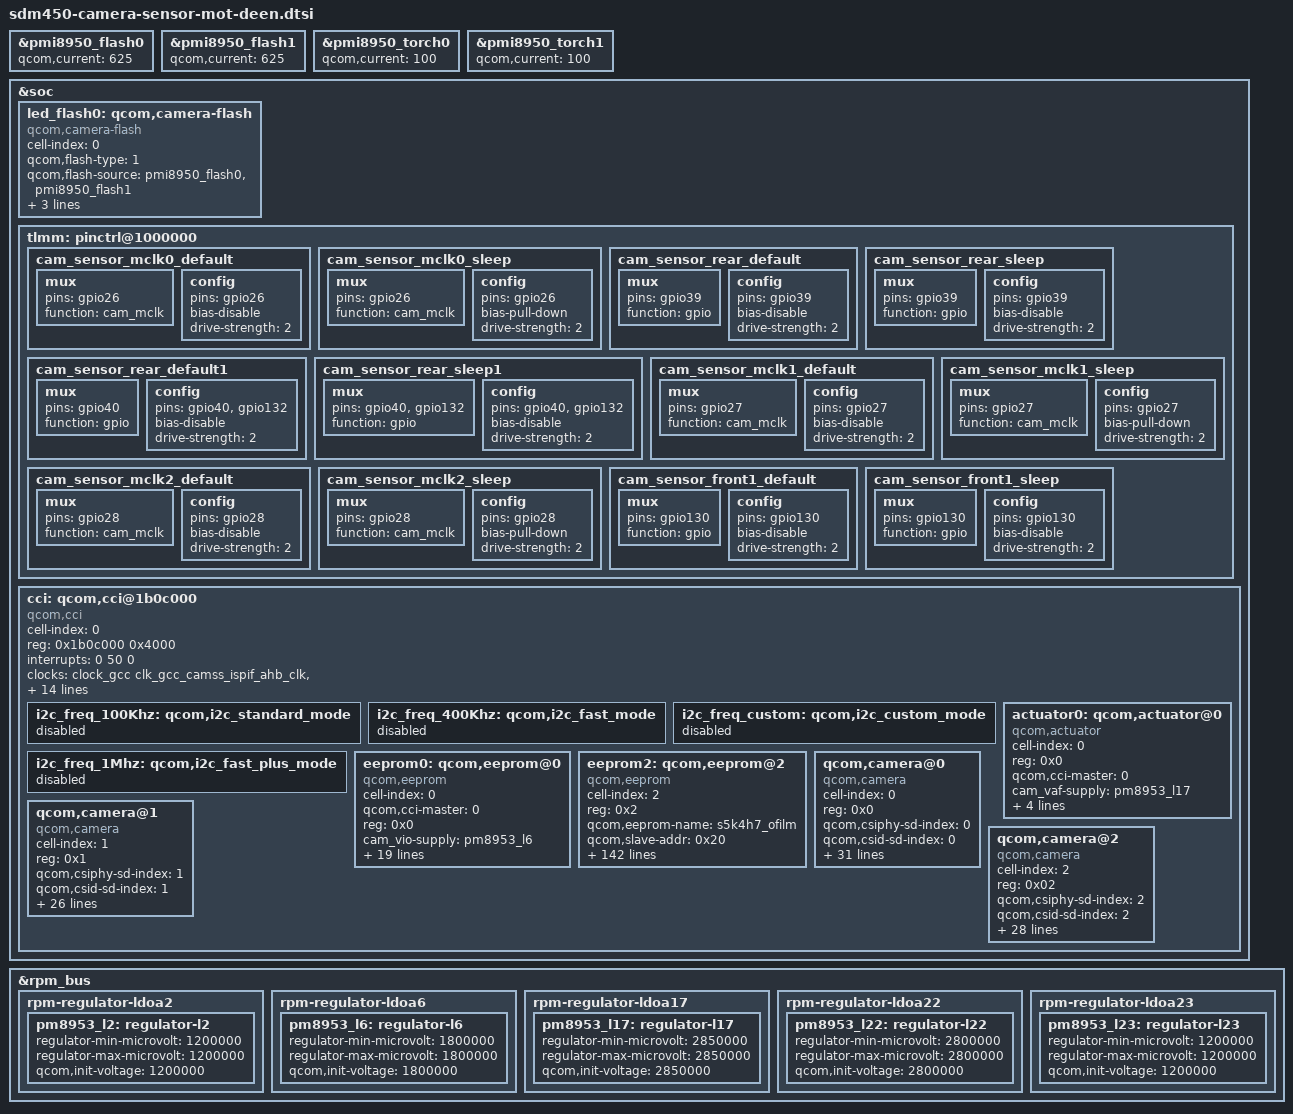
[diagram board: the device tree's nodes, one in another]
/*
 * Copyright (c) 2018, The Linux Foundation. All rights reserved.
 *
 * This program is free software; you can redistribute it and/or modify
 * it under the terms of the GNU General Public License version 2 and
 * only version 2 as published by the Free Software Foundation.
 *
 * This program is distributed in the hope that it will be useful,
 * but WITHOUT ANY WARRANTY; without even the implied warranty of
 * MERCHANTABILITY or FITNESS FOR A PARTICULAR PURPOSE.  See the
 * GNU General Public License for more details.
 */
&pmi8950_flash0 {
	qcom,current = <625>;
};

&pmi8950_flash1 {
	qcom,current = <625>;
};

&pmi8950_torch0 {
	qcom,current = <100>;
};

&pmi8950_torch1 {
	qcom,current = <100>;
};

&soc {
	led_flash0: qcom,camera-flash {
		cell-index = <0>;
		compatible = "qcom,camera-flash";
		qcom,flash-type = <1>;
		qcom,flash-source = <&pmi8950_flash0 &pmi8950_flash1>;
		qcom,torch-source = <&pmi8950_torch0 &pmi8950_torch1>;
		qcom,switch-source = <&pmi8950_switch>;
	};
};

&cci {
	actuator0: qcom,actuator@0 {
		cell-index = <0>;
		reg = <0x0>;
		compatible = "qcom,actuator";
		qcom,cci-master = <0>;
		cam_vaf-supply = <&pm8953_l17>;
		qcom,cam-vreg-name = "cam_vaf";
		qcom,cam-vreg-min-voltage = <2850000>;
		qcom,cam-vreg-max-voltage = <2850000>;
		qcom,cam-vreg-op-mode = <80000>;
	};

	eeprom0: qcom,eeprom@0 {
		cell-index = <0>;
		compatible = "qcom,eeprom";
		qcom,cci-master = <0>;
		reg = <0x0>;
		cam_vio-supply = <&pm8953_l6>;
		cam_vdig-supply = <&pm8953_l2>;
		cam_vaf-supply = <&pm8953_l17>;
		qcom,cam-vreg-name = "cam_vio", "cam_vdig", "cam_vaf";
		qcom,cam-vreg-min-voltage = <0 1200000 2850000>;
		qcom,cam-vreg-max-voltage = <0 1200000 2850000>;
		qcom,cam-vreg-op-mode = <0 105000 100000>;
		pinctrl-names = "cam_default", "cam_suspend";
		pinctrl-0 = <&cam_sensor_mclk0_default
				&cam_sensor_rear_default>;
		pinctrl-1 = <&cam_sensor_mclk0_sleep
				&cam_sensor_rear_sleep>;
		gpios = <&tlmm 26 0>,
			<&tlmm 39 0>;
		qcom,gpio-reset = <1>;
		qcom,gpio-req-tbl-num = <0 1>;
		qcom,gpio-req-tbl-flags = <1 0>;
		qcom,gpio-req-tbl-label = "CAMIF_MCLK0",
			"CAM_RESET0";
		status = "ok";
		clocks = <&clock_gcc clk_mclk0_clk_src>,
				<&clock_gcc clk_gcc_camss_mclk0_clk>;
		clock-names = "cam_src_clk", "cam_clk";
		qcom,clock-rates = <24000000 0>;
	};



	eeprom2: qcom,eeprom@2 {
		cell-index = <2>;
		reg = <0x2>;
		compatible = "qcom,eeprom";
		qcom,eeprom-name = "s5k4h7_ofilm";
		qcom,slave-addr = <0x20>;
		qcom,cci-master = <1>;
		qcom,num-blocks = <36>;

		qcom,cmm-data-support = <1>;
		qcom,cmm-data-compressed = <0>;
		qcom,cmm-data-offset = <10>;
		qcom,cmm-data-size = <20>;

		//read page 21
		qcom,page0 = <1 0x0100 2 0x01 1 0>;//STREAM ON
		qcom,poll0 = <0 0x0 2 0x0 1 0>;
		qcom,mem0 = <0 0x0 2 0x0 1 0>;

		qcom,page1 = <1 0x0A02 2 0x15 1 0>;//PAGE 20
		qcom,poll1 = <0 0x0 2 0x0 1 0>;
		qcom,mem1 = <0 0x0 2 0x0 1 0>;

		qcom,page2 = <1 0x0A00 2 0x01 1 0>;//ENABLE READ
		qcom,poll2 = <0 0x0 2 0x0 1 0>;
		qcom,mem2 = <64 0x0A04 2 0x0 1 0>;//READ PAGE 20
		//read page 22
		qcom,page3 = <1 0x0100 2 0x01 1 0>;
		qcom,poll3 = <0 0x0 2 0x0 1 0>;
		qcom,mem3 = <0 0x0 2 0x0 1 0>;

		qcom,page4 = <1 0x0A02 2 0x16 1 0>;
		qcom,poll4 = <0 0x0 2 0x0 1 0>;
		qcom,mem4 = <0 0x0 2 0x0 1 0>;

		qcom,page5 = <1 0x0A00 2 0x01 1 0>;
		qcom,poll5 = <0 0x0 2 0x0 1 0>;
		qcom,mem5 = <64 0x0A04 2 0x0 1 0>;
		//read page 23

		qcom,page6 = <1 0x0100 2 0x01 1 0>;
		qcom,poll6 = <0 0x0 2 0x0 1 0>;
		qcom,mem6 = <0 0x0 2 0x0 1 0>;

		qcom,page7 = <1 0x0A02 2 0x17 1 0>;
		qcom,poll7 = <0 0x0 2 0x0 1 0>;
		qcom,mem7 = <0 0x0 2 0x0 1 0>;

		qcom,page8 = <1 0x0A00 2 0x01 1 0>;
		qcom,poll8 = <0 0x0 2 0x0 1 0>;
		qcom,mem8 = <64 0x0A04 2 0x0 1 0>;//tes1 pass


		//read page 24
		qcom,page9 = <1 0x0100 2 0x01 1 0>;
		qcom,poll9 = <0 0x0 2 0x0 1 0>;
		qcom,mem9 = <0 0x0 2 0x0 1 0>;

		qcom,page10 = <1 0x0A02 2 0x18 1 0>;
		qcom,poll10 = <0 0x0 2 0x0 1 0>;
		qcom,mem10 = <0 0x0 2 0x0 1 0>;

		qcom,page11 = <1 0x0A00 2 0x01 1 0>;
		qcom,poll11 = <0 0x0 2 0x0 1 0>;
		qcom,mem11 = <64 0x0A04 2 0x0 1 0>;
		//read page 25
		qcom,page12 = <1 0x0100 2 0x01 1 0>;
		qcom,poll12 = <0 0x0 2 0x0 1 0>;
		qcom,mem12 = <0 0x0 2 0x0 1 0>;

		qcom,page13 = <1 0x0A02 2 0x19 1 0>;
		qcom,poll13 = <0 0x0 2 0x0 1 0>;
		qcom,mem13 = <0 0x0 2 0x0 1 0>;

		qcom,page14 = <1 0x0A00 2 0x01 1 0>;
		qcom,poll14 = <0 0x0 2 0x0 1 0>;
		qcom,mem14 = <64 0x0A04 2 0x0 1 0>;

		//read page 26
		qcom,page15 = <1 0x0100 2 0x01 1 0>;
		qcom,poll15 = <0 0x0 2 0x0 1 0>;
		qcom,mem15 = <0 0x0 2 0x0 1 0>;

		qcom,page16 = <1 0x0A02 2 0x1A 1 0>;
		qcom,poll16 = <0 0x0 2 0x0 1 0>;
		qcom,mem16 = <0 0x0 2 0x0 1 0>;

		qcom,page17 = <1 0x0A00 2 0x01 1 0>;
		qcom,poll17 = <0 0x0 2 0x0 1 0>;
		qcom,mem17 = <64 0x0A04 2 0x0 1 0>;

		//read page 27
		qcom,page18 = <1 0x0100 2 0x01 1 0>;
		qcom,poll18 = <0 0x0 2 0x0 1 0>;
		qcom,mem18 = <0 0x0 2 0x0 1 0>;

		qcom,page19 = <1 0x0A02 2 0x1B 1 0>;
		qcom,poll19 = <0 0x0 2 0x0 1 0>;
		qcom,mem19 = <0 0x0 2 0x0 1 0>;

		qcom,page20 = <1 0x0A00 2 0x01 1 0>;
		qcom,poll20 = <0 0x0 2 0x0 1 0>;
		qcom,mem20 = <64 0x0A04 2 0x0 1 0>;
		//read page 28
		qcom,page21 = <1 0x0100 2 0x01 1 0>;
		qcom,poll21 = <0 0x0 2 0x0 1 0>;
		qcom,mem21 = <0 0x0 2 0x0 1 0>;

		qcom,page22 = <1 0x0A02 2 0x1C 1 0>;
		qcom,poll22 = <0 0x0 2 0x0 1 0>;
		qcom,mem22 = <0 0x0 2 0x0 1 0>;

		qcom,page23 = <1 0x0A00 2 0x01 1 0>;
		qcom,poll23 = <0 0x0 2 0x0 1 0>;
		qcom,mem23 = <64 0x0A04 2 0x0 1 0>;

		//read page 29
		qcom,page24 = <1 0x0100 2 0x01 1 0>;
		qcom,poll24 = <0 0x0 2 0x0 1 0>;
		qcom,mem24 = <0 0x0 2 0x0 1 0>;

		qcom,page25 = <1 0x0A02 2 0x1D 1 0>;
		qcom,poll25 = <0 0x0 2 0x0 1 0>;
		qcom,mem25 = <0 0x0 2 0x0 1 0>;

		qcom,page26 = <1 0x0A00 2 0x01 1 0>;
		qcom,poll26 = <0 0x0 2 0x0 1 0>;
		qcom,mem26 = <64 0x0A04 2 0x0 1 0>;

		//read page 30
		qcom,page27 = <1 0x0100 2 0x01 1 0>;
		qcom,poll27 = <0 0x0 2 0x0 1 0>;
		qcom,mem27 = <0 0x0 2 0x0 1 0>;

		qcom,page28 = <1 0x0A02 2 0x1E 1 0>;
		qcom,poll28 = <0 0x0 2 0x0 1 0>;
		qcom,mem28 = <0 0x0 2 0x0 1 0>;

		qcom,page29 = <1 0x0A00 2 0x01 1 0>;
		qcom,poll29 = <0 0x0 2 0x0 1 0>;
		qcom,mem29 = <64 0x0A04 2 0x0 1 0>;//test2 failed

		//read page 31
		qcom,page30 = <1 0x0100 2 0x01 1 0>;
		qcom,poll30 = <0 0x0 2 0x0 1 0>;
		qcom,mem30 = <0 0x0 2 0x0 1 0>;

		qcom,page31 = <1 0x0A02 2 0x1F 1 0>;
		qcom,poll31 = <0 0x0 2 0x0 1 0>;
		qcom,mem31 = <0 0x0 2 0x0 1 0>;

		qcom,page32 = <1 0x0A00 2 0x01 1 0>;
		qcom,poll32 = <0 0x0 2 0x0 1 0>;
		qcom,mem32 = <64 0x0A04 2 0x0 1 0>;

		//read page 32
		qcom,page33 = <1 0x0100 2 0x01 1 0>;
		qcom,poll33 = <0 0x0 2 0x0 1 0>;
		qcom,mem33 = <0 0x0 2 0x0 1 0>;

		qcom,page34 = <1 0x0A02 2 0x20 1 0>;
		qcom,poll34 = <0 0x0 2 0x0 1 0>;
		qcom,mem34 = <0 0x0 2 0x0 1 0>;

		qcom,page35 = <1 0x0A00 2 0x01 1 0>;
		qcom,poll35 = <0 0x0 2 0x0 1 0>;
		qcom,mem35 = <64 0x0A04 2 0x0 1 0>;

		cam_vdig-supply = <&pm8953_l23>;
		cam_vio-supply = <&pm8953_l6>;
		cam_vana-supply = <&pm8953_l22>;
		qcom,cam-vreg-name = "cam_vdig", "cam_vio", "cam_vana";
		qcom,cam-vreg-min-voltage = <1200000 0 2800000>;
		qcom,cam-vreg-max-voltage = <1200000 0 2800000>;
		qcom,cam-vreg-op-mode = <105000 0 80000>;
		pinctrl-names = "cam_default", "cam_suspend";
		pinctrl-0 = <&cam_sensor_mclk1_default
			&cam_sensor_front1_default>;
		pinctrl-1 = <&cam_sensor_mclk1_sleep
			&cam_sensor_front1_sleep>;
		gpios = <&tlmm 27 0>,
			<&tlmm 130 0>;
		qcom,gpio-reset = <1>;
		qcom,gpio-req-tbl-num = <0 1>;
		qcom,gpio-req-tbl-flags = <1 0>;
		qcom,gpio-req-tbl-label = "CAMIF_MCLK2", "CAM_RESET2";

		qcom,cam-power-seq-type = "sensor_vreg",
			"sensor_vreg", "sensor_vreg",
			"sensor_gpio", "sensor_clk";
		qcom,cam-power-seq-val = "cam_vana",
			"cam_vdig", "cam_vio",
			"sensor_gpio_reset",
			"sensor_cam_mclk";
		qcom,cam-power-seq-cfg-val = <0 0 0 1 24000000>;
		qcom,cam-power-seq-delay = <1 1 5 5 5>;

		status = "ok";
		clocks = <&clock_gcc clk_mclk1_clk_src>,
				<&clock_gcc clk_gcc_camss_mclk1_clk>;
		clock-names = "cam_src_clk", "cam_clk";
		qcom,clock-rates = <24000000 0>;
	};

	/* OV13855 REAR */
	qcom,camera@0 {
		cell-index = <0>;
		compatible = "qcom,camera";
		reg = <0x0>;
		qcom,csiphy-sd-index = <0>;
		qcom,csid-sd-index = <0>;
		qcom,mount-angle = <90>;
		qcom,led-flash-src = <&led_flash0>;
		qcom,actuator-src = <&actuator0>;
		qcom,eeprom-src = <&eeprom0>;
		cam_vio-supply = <&pm8953_l6>;
		cam_vdig-supply = <&pm8953_l2>;
		cam_vaf-supply = <&pm8953_l17>;
		cam_vana-supply = <&pm8953_l22>;

		qcom,cam-vreg-name = "cam_vio", "cam_vdig", "cam_vaf",
						"cam_vana";
		qcom,cam-vreg-min-voltage = <0 1200000 2850000 2800000>;
		qcom,cam-vreg-max-voltage = <0 1200000 2850000 2800000>;
		qcom,cam-vreg-op-mode = <0 105000 100000 80000>;
		pinctrl-names = "cam_default", "cam_suspend";
		pinctrl-0 = <&cam_sensor_mclk0_default
				&cam_sensor_rear_default>;
		pinctrl-1 = <&cam_sensor_mclk0_sleep &cam_sensor_rear_sleep>;
		gpios = <&tlmm 26 0>,
			<&tlmm 39 0>;
		qcom,gpio-reset = <1>;
		qcom,gpio-req-tbl-num = <0 1>;
		qcom,gpio-req-tbl-flags = <1 0>;
		qcom,gpio-req-tbl-label = "CAMIF_MCLK0",
			"CAM_RESET0";
		qcom,sensor-position = <0>;
		qcom,sensor-mode = <0>;
		qcom,cci-master = <0>;
		status = "ok";
		clocks = <&clock_gcc clk_mclk0_clk_src>,
				<&clock_gcc clk_gcc_camss_mclk0_clk>;
		clock-names = "cam_src_clk", "cam_clk";
		qcom,clock-rates = <24000000 0>;
	};
/*gc2375 backaux */
	qcom,camera@1 {
		cell-index = <1>;
		compatible = "qcom,camera";
		reg = <0x1>;
		qcom,csiphy-sd-index = <1>;
		qcom,csid-sd-index = <1>;
		qcom,mount-angle = <90>;
		//qcom,eeprom-src = <&eeprom2>;
		cam_vdig-supply = <&pm8953_l6>;
		cam_vana-supply = <&pm8953_l22>;
		cam_vio-supply = <&pm8953_l6>;
		qcom,cam-vreg-name = "cam_vdig", "cam_vio", "cam_vana";
		qcom,cam-vreg-min-voltage = <1800000 0 2800000>;
		qcom,cam-vreg-max-voltage = <1800000 0 2800000>;
		qcom,cam-vreg-op-mode = <200000 0 80000>;
		pinctrl-names = "cam_default", "cam_suspend";
		pinctrl-0 = <&cam_sensor_mclk2_default
				&cam_sensor_rear_default1>;
		pinctrl-1 = <&cam_sensor_mclk2_sleep
				&cam_sensor_rear_sleep1>;
		gpios = <&tlmm 28 0>,
			<&tlmm 40 0>,
			<&tlmm 132 0>;
		qcom,gpio-reset = <1>;
		qcom,gpio-standby = <2>;
		qcom,gpio-req-tbl-num = <0 1 2>;
		qcom,gpio-req-tbl-flags = <1 0 0>;
		qcom,gpio-req-tbl-label = "CAMIF_MCLK1",
			"CAM_RESET1",
			"CAM_STANDBY1";
		qcom,sensor-position = <0x000>;
		qcom,sensor-mode = <0>;
		qcom,cci-master = <0>;
		status = "ok";
		clocks = <&clock_gcc clk_mclk2_clk_src>,
				<&clock_gcc clk_gcc_camss_mclk2_clk>;
		clock-names = "cam_src_clk", "cam_clk";
		qcom,clock-rates = <24000000 0>;
	};

	/* S5K4H7 */
	qcom,camera@2 {
		cell-index = <2>;
		compatible = "qcom,camera";
		reg = <0x02>;
		qcom,csiphy-sd-index = <2>;
		qcom,csid-sd-index = <2>;
		qcom,mount-angle = <90>;
		qcom,led-flash-src = <&led_flash0>;
		qcom,eeprom-src = <&eeprom2>;
		cam_vdig-supply = <&pm8953_l23>;
		cam_vio-supply = <&pm8953_l6>;
		cam_vana-supply = <&pm8953_l22>;
		qcom,cam-vreg-name = "cam_vdig", "cam_vio", "cam_vana";
		qcom,cam-vreg-min-voltage = <1200000 0 2800000>;
		qcom,cam-vreg-max-voltage = <1200000 0 2800000>;
		qcom,cam-vreg-op-mode = <105000 0 80000>;
		qcom,gpio-no-mux = <0>;
		pinctrl-names = "cam_default", "cam_suspend";
		pinctrl-0 = <&cam_sensor_mclk1_default
				&cam_sensor_front1_default>;
		pinctrl-1 = <&cam_sensor_mclk1_sleep
				&cam_sensor_front1_sleep>;
		gpios = <&tlmm 27 0>,
			<&tlmm 130 0>;
		qcom,gpio-reset = <1>;
		qcom,gpio-req-tbl-num = <0 1>;
		qcom,gpio-req-tbl-flags = <1 0>;
		qcom,gpio-req-tbl-label = "CAMIF_MCLK2",
					  "CAM_RESET2";
		qcom,sensor-position = <1>;
		qcom,sensor-mode = <1>;
		qcom,cci-master = <1>;
		status = "ok";
		clocks = <&clock_gcc clk_mclk1_clk_src>,
				<&clock_gcc clk_gcc_camss_mclk1_clk>;
		clock-names = "cam_src_clk", "cam_clk";
		qcom,clock-rates = <24000000 0>;
	};

};

&soc {
	tlmm: pinctrl@1000000 {

		cam_sensor_mclk0_default: cam_sensor_mclk0_default {
			/* MCLK0 */
			mux {
				/* CLK, DATA */
				pins = "gpio26";
				function = "cam_mclk";
			};

			config {
				pins = "gpio26";
				bias-disable; /* No PULL */
				drive-strength = <2>; /* 2 MA */
			};
		};

		cam_sensor_mclk0_sleep: cam_sensor_mclk0_sleep {
			/* MCLK0 */
			mux {
				/* CLK, DATA */
				pins = "gpio26";
				function = "cam_mclk";
			};

			config {
				pins = "gpio26";
				bias-pull-down; /* PULL DOWN */
				drive-strength = <2>; /* 2 MA */
			};
		};

		cam_sensor_rear_default: cam_sensor_rear_default {
				/* RESET, STANDBY */
			mux {
					pins = "gpio39";
				function = "gpio";
			};

				config {
					pins = "gpio39";
					bias-disable; /* No PULL */
					drive-strength = <2>; /* 2 MA */
				};
			};

			cam_sensor_rear_sleep: cam_sensor_rear_sleep {
				/* RESET, STANDBY */
				mux {
					pins = "gpio39";
					function = "gpio";
				};

				config {
					pins = "gpio39";
					bias-disable; /* No PULL */
					drive-strength = <2>; /* 2 MA */
				};
			};

		cam_sensor_rear_default1: cam_sensor_rear_default1 {
			/* RESET*/
			mux {
				pins = "gpio40";
				function = "gpio";
			};

				config {
					pins = "gpio40","gpio132";
					bias-disable; /* No PULL */
					drive-strength = <2>; /* 2 MA */
				};
			};

			cam_sensor_rear_sleep1: cam_sensor_rear_sleep1 {
				/* RESET*/
				mux {
					pins = "gpio40","gpio132";
					function = "gpio";
				};

				config {
					pins = "gpio40","gpio132";
					bias-disable; /* No PULL */
					drive-strength = <2>; /* 2 MA */
				};
			};

		cam_sensor_mclk1_default: cam_sensor_mclk1_default {
			/* MCLK1 */
			mux {
				/* CLK, DATA */
				pins = "gpio27";
				function = "cam_mclk";
			};

			config {
				pins = "gpio27";
				bias-disable; /* No PULL */
				drive-strength = <2>; /* 2 MA */
			};
		};

		cam_sensor_mclk1_sleep: cam_sensor_mclk1_sleep {
			/* MCLK1 */
			mux {
				/* CLK, DATA */
				pins = "gpio27";
				function = "cam_mclk";
			};

			config {
				pins = "gpio27";
				bias-pull-down; /* PULL DOWN */
				drive-strength = <2>; /* 2 MA */
			};
		};


		cam_sensor_mclk2_default: cam_sensor_mclk2_default {
			/* MCLK2 */
			mux {
				/* CLK, DATA */
				pins = "gpio28";
				function = "cam_mclk";
			};

			config {
				pins = "gpio28";
				bias-disable; /* No PULL */
				drive-strength = <2>; /* 2 MA */
			};
		};

		cam_sensor_mclk2_sleep: cam_sensor_mclk2_sleep {
			/* MCLK2 */
			mux {
				/* CLK, DATA */
				pins = "gpio28";
				function = "cam_mclk";
			};

			config {
				pins = "gpio28";
				bias-pull-down; /* PULL DOWN */
				drive-strength = <2>; /* 2 MA */
			};
		};

		cam_sensor_front1_default: cam_sensor_front1_default {
			/* RESET, STANDBY */
			mux {
				pins = "gpio130";
				function = "gpio";
			};

			config {
				pins = "gpio130";
				bias-disable; /* No PULL */
				drive-strength = <2>; /* 2 MA */
			};
		};

		cam_sensor_front1_sleep: cam_sensor_front1_sleep {
			/* RESET, STANDBY */
			mux {
				pins = "gpio130";
				function = "gpio";
			};

			config {
				pins = "gpio130";
				bias-disable; /* No PULL */
				drive-strength = <2>; /* 2 MA */
			};
		};
	};

	cci: qcom,cci@1b0c000 {
		status = "ok";
		cell-index = <0>;
		compatible = "qcom,cci";
		reg = <0x1b0c000 0x4000>;
		#address-cells = <1>;
		#size-cells = <0>;
		reg-names = "cci";
		interrupts = <0 50 0>;
		interrupt-names = "cci";
		clocks = <&clock_gcc clk_gcc_camss_ispif_ahb_clk>,
			<&clock_gcc clk_cci_clk_src>,
			<&clock_gcc clk_gcc_camss_cci_ahb_clk>,
			<&clock_gcc clk_gcc_camss_cci_clk>,
			<&clock_gcc clk_gcc_camss_ahb_clk>,
			<&clock_gcc clk_gcc_camss_top_ahb_clk>;
		clock-names = "ispif_ahb_clk", "cci_src_clk",
			"cci_ahb_clk", "camss_cci_clk",
			"camss_ahb_clk", "camss_top_ahb_clk";
		qcom,clock-rates = <61540000 19200000 0 0 0 0>,
				<61540000 37500000 0 0 0 0>;
		pinctrl-names = "cci_default", "cci_suspend";
			pinctrl-0 = <&cci0_active &cci1_active>;
			pinctrl-1 = <&cci0_suspend &cci1_suspend>;
		gpios = <&tlmm 29 0>,
			<&tlmm 30 0>,
			<&tlmm 31 0>,
			<&tlmm 32 0>;
		qcom,gpio-tbl-num = <0 1 2 3>;
		qcom,gpio-tbl-flags = <1 1 1 1>;
		qcom,gpio-tbl-label = "CCI_I2C_DATA0",
						"CCI_I2C_CLK0",
						"CCI_I2C_DATA1",
						"CCI_I2C_CLK1";
		i2c_freq_100Khz: qcom,i2c_standard_mode {
			status = "disabled";
		};
		i2c_freq_400Khz: qcom,i2c_fast_mode {
			status = "disabled";
		};
		i2c_freq_custom: qcom,i2c_custom_mode {
			status = "disabled";
		};

		i2c_freq_1Mhz: qcom,i2c_fast_plus_mode {
			status = "disabled";
		};

	};
};

&rpm_bus {
	rpm-regulator-ldoa2 {
		status = "okay";
		pm8953_l2: regulator-l2 {
			regulator-min-microvolt = <1200000>;
			regulator-max-microvolt = <1200000>;
			qcom,init-voltage = <1200000>;
			status = "okay";
		};
	};

	rpm-regulator-ldoa6 {
		status = "okay";
		pm8953_l6: regulator-l6 {
			regulator-min-microvolt = <1800000>;
			regulator-max-microvolt = <1800000>;
			qcom,init-voltage = <1800000>;
			status = "okay";
		};
	};

	rpm-regulator-ldoa17 {
		status = "okay";
		pm8953_l17: regulator-l17 {
			regulator-min-microvolt = <2850000>;
			regulator-max-microvolt = <2850000>;
			qcom,init-voltage = <2850000>;
			status = "okay";
		};
	};

	rpm-regulator-ldoa22 {
		status = "okay";
		pm8953_l22: regulator-l22 {
			regulator-min-microvolt = <2800000>;
			regulator-max-microvolt = <2800000>;
			qcom,init-voltage = <2800000>;
			status = "okay";
		};
	};
	rpm-regulator-ldoa23 {
		status = "okay";
		pm8953_l23: regulator-l23 {
			regulator-min-microvolt = <1200000>;
			regulator-max-microvolt = <1200000>;
			qcom,init-voltage = <1200000>;
			status = "okay";
		};
	};};
